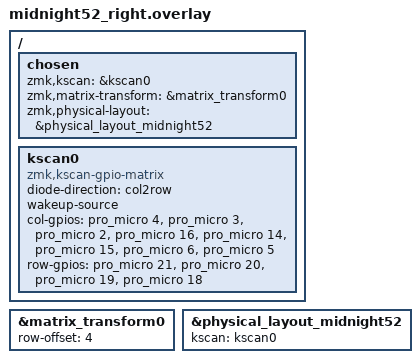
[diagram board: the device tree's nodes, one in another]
#include "midnight52.dtsi"

/ {
    chosen {
        zmk,kscan = &kscan0;
        zmk,matrix-transform = &matrix_transform0;
        zmk,physical-layout = &physical_layout_midnight52;
    };

    kscan0: kscan0 {
        compatible = "zmk,kscan-gpio-matrix";
            diode-direction = "col2row";
        wakeup-source;

        col-gpios
            = <&pro_micro 4 (GPIO_ACTIVE_HIGH | GPIO_PULL_DOWN)>
            , <&pro_micro 3 (GPIO_ACTIVE_HIGH | GPIO_PULL_DOWN)>
            , <&pro_micro 2 (GPIO_ACTIVE_HIGH | GPIO_PULL_DOWN)>
            , <&pro_micro 16 (GPIO_ACTIVE_HIGH | GPIO_PULL_DOWN)>
            , <&pro_micro 14 (GPIO_ACTIVE_HIGH | GPIO_PULL_DOWN)>
            , <&pro_micro 15 (GPIO_ACTIVE_HIGH | GPIO_PULL_DOWN)>
            , <&pro_micro 6 (GPIO_ACTIVE_HIGH | GPIO_PULL_DOWN)>
            , <&pro_micro 5 (GPIO_ACTIVE_HIGH | GPIO_PULL_DOWN)>
            ;

        row-gpios
            = <&pro_micro 21 GPIO_ACTIVE_HIGH>
            , <&pro_micro 20 GPIO_ACTIVE_HIGH>
            , <&pro_micro 19 GPIO_ACTIVE_HIGH>
            , <&pro_micro 18 GPIO_ACTIVE_HIGH>
            ;
    };
};

&matrix_transform0 {
    row-offset = <4>;
};

&physical_layout_midnight52 {
    kscan = <&kscan0>;
};

